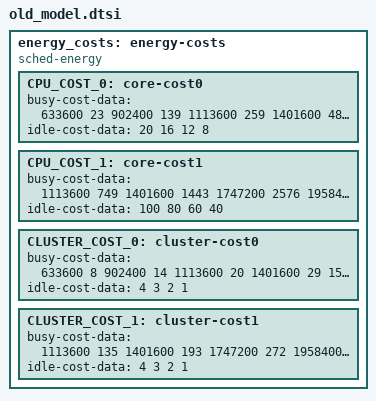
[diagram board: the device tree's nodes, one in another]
	energy_costs: energy-costs {
		compatible = "sched-energy";

		CPU_COST_0: core-cost0 {
			busy-cost-data = <
				 633600 23
				 902400 139
				1113600 259
				1401600 482
				1536000 690
				1747200 870
				1843200 1102
			>;
			idle-cost-data = <
				20 16 12 8
			>;
		};
		CPU_COST_1: core-cost1 {
			busy-cost-data = <
				1113600 749
				1401600 1443
				1747200 2576
				1958400 4153
				2150400 5941
				2208000 6688
			>;
			idle-cost-data = <
				100 80 60 40
			>;
		};
		CLUSTER_COST_0: cluster-cost0 {
			busy-cost-data = <
				 633600 8
				 902400 14
				1113600 20
				1401600 29
				1536000 35
				1747200 49
				1843200 62
			>;
			idle-cost-data = <
				4 3 2 1
			>;
		};
		CLUSTER_COST_1: cluster-cost1 {
			busy-cost-data = <
				1113600 135
				1401600 193
				1747200 272
				1958400 363
				2150400 519
				2208000 585
			>;
			idle-cost-data = <
				4 3 2 1
			>;
		};
	};
